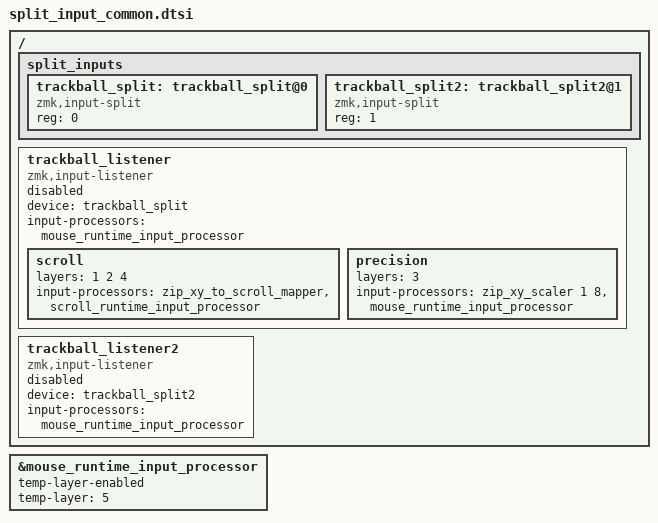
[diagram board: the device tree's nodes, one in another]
#include <input/processors.dtsi>
#include <input/processors/runtime-input-processor.dtsi>

/ {
  split_inputs {
    #address-cells = <1>;
    #size-cells = <0>;

    /* right half sensor, relayed from peripheral_right */
    trackball_split: trackball_split@0 {
      compatible = "zmk,input-split";
      reg = <0>;
    };
    /* left half sensor, relayed from peripheral_left */
    trackball_split2: trackball_split2@1 {
      compatible = "zmk,input-split";
      reg = <1>;
    };
  };

  /* right trackball: move + scroll on layers 1,2,4 (Navi/Symbol/Flash) +
     precision (1/8 speed) on layer 3 (Modify). Layer 3 is excluded from the
     scroll set (rather than relying on child-node match order) so the two
     stay mutually exclusive. */
  trackball_listener: trackball_listener {
    compatible = "zmk,input-listener";
    status = "disabled";
    device = <&trackball_split>;
    input-processors = <&mouse_runtime_input_processor>;

    scroll {
      layers = <1 2 4>;
      input-processors = <&zip_xy_to_scroll_mapper &scroll_runtime_input_processor>;
    };

    precision {
      layers = <3>;
      input-processors = <&zip_xy_scaler 1 8 &mouse_runtime_input_processor>;
    };
  };

  /* left trackball: move only (matches the config as shipped - no scroll/precision wiring) */
  trackball_listener2: trackball_listener2 {
    compatible = "zmk,input-listener";
    status = "disabled";
    device = <&trackball_split2>;
    input-processors = <&mouse_runtime_input_processor>;
  };
};

&mouse_runtime_input_processor {
  /* auto-activate a mouse layer while either trackball is moving on the base layer,
     matching the ib_tog_layer 5 behavior both trackballs triggered before migration */
  temp-layer-enabled;
  temp-layer = <5>;
};
